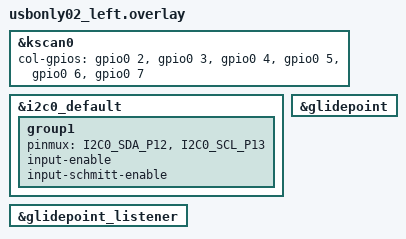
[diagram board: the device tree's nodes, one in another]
#include "usbonly02.dtsi"

&kscan0 {
    col-gpios
        = <&gpio0 2 GPIO_ACTIVE_HIGH>
        , <&gpio0 3  GPIO_ACTIVE_HIGH>
        , <&gpio0 4  GPIO_ACTIVE_HIGH>
        , <&gpio0 5  GPIO_ACTIVE_HIGH>
        , <&gpio0 6  GPIO_ACTIVE_HIGH>
        , <&gpio0 7  GPIO_ACTIVE_HIGH>
        ;
};


&i2c0_default {
    group1 {
	    pinmux = <I2C0_SDA_P12>, <I2C0_SCL_P13>;
	    input-enable;
	    input-schmitt-enable;
	};
    status = "okay";
};

&glidepoint  {
    status = "okay";
};

&glidepoint_listener {
    status = "okay";
};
